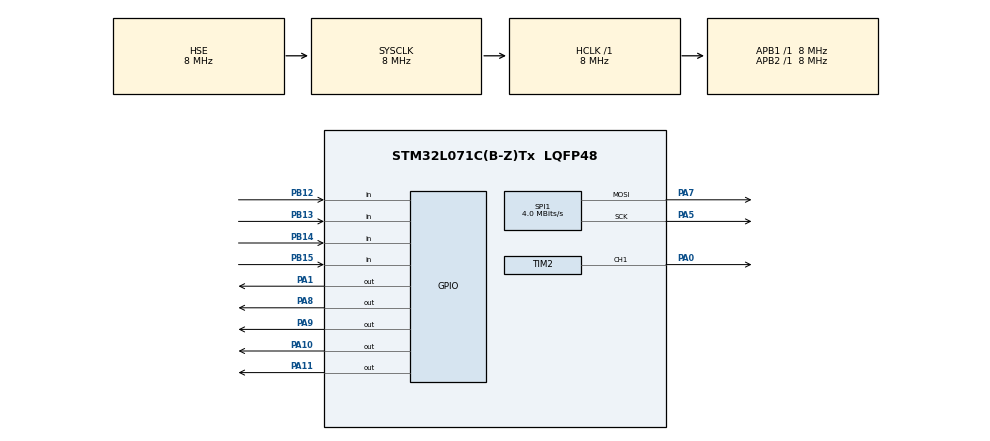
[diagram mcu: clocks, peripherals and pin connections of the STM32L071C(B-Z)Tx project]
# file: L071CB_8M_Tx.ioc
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Mcu.Family=STM32L0
Mcu.Name=STM32L071C(B-Z)Tx
Mcu.Package=LQFP48
NVIC.TIM6_IRQn=true\:0\:0\:false\:false\:true\:true\:true
PA0.Signal=S_TIM2_CH1
PA1.GPIO_Speed=GPIO_SPEED_FREQ_VERY_HIGH
PA1.PinState=GPIO_PIN_SET
PA1.Signal=GPIO_Output
PA10.GPIO_ModeDefaultOutputPP=GPIO_MODE_OUTPUT_PP
PA10.GPIO_PuPd=GPIO_PULLUP
PA10.GPIO_Speed=GPIO_SPEED_FREQ_VERY_HIGH
PA10.PinState=GPIO_PIN_SET
PA10.Signal=GPIO_Output
PA11.GPIO_ModeDefaultOutputPP=GPIO_MODE_OUTPUT_PP
PA11.GPIO_PuPd=GPIO_PULLUP
PA11.GPIO_Speed=GPIO_SPEED_FREQ_VERY_HIGH
PA11.PinState=GPIO_PIN_SET
PA11.Signal=GPIO_Output
PA13.Mode=Serial_Wire
PA13.Signal=SYS_SWDIO
PA14.Mode=Serial_Wire
PA14.Signal=SYS_SWCLK
PA5.Mode=TX_Only_Simplex_Unidirect_Master
PA5.Signal=SPI1_SCK
PA7.Mode=TX_Only_Simplex_Unidirect_Master
PA7.Signal=SPI1_MOSI
PA8.GPIO_ModeDefaultOutputPP=GPIO_MODE_OUTPUT_PP
PA8.GPIO_PuPd=GPIO_PULLUP
PA8.GPIO_Speed=GPIO_SPEED_FREQ_VERY_HIGH
PA8.PinState=GPIO_PIN_SET
PA8.Signal=GPIO_Output
PA9.GPIO_ModeDefaultOutputPP=GPIO_MODE_OUTPUT_PP
PA9.GPIO_PuPd=GPIO_PULLUP
PA9.GPIO_Speed=GPIO_SPEED_FREQ_VERY_HIGH
PA9.PinState=GPIO_PIN_SET
PA9.Signal=GPIO_Output
PB12.GPIO_Mode=GPIO_MODE_INPUT
PB12.GPIO_PuPd=GPIO_PULLDOWN
PB12.Signal=GPIO_Input
PB13.GPIO_Mode=GPIO_MODE_INPUT
PB13.GPIO_PuPd=GPIO_PULLDOWN
PB13.Signal=GPIO_Input
PB14.GPIO_Mode=GPIO_MODE_INPUT
PB14.GPIO_PuPd=GPIO_PULLDOWN
PB14.Signal=GPIO_Input
PB15.GPIO_Mode=GPIO_MODE_INPUT
PB15.GPIO_PuPd=GPIO_PULLDOWN
PB15.Signal=GPIO_Input
PC14-OSC32_IN.Mode=LSE-External-Oscillator
PC14-OSC32_IN.Signal=RCC_OSC32_IN
PC15-OSC32_OUT.Mode=LSE-External-Oscillator
PC15-OSC32_OUT.Signal=RCC_OSC32_OUT
PH0-OSC_IN.Mode=HSE-External-Oscillator
PH0-OSC_IN.Signal=RCC_OSC_IN
PH1-OSC_OUT.Mode=HSE-External-Oscillator
PH1-OSC_OUT.Signal=RCC_OSC_OUT
ProjectManager.HeapSize=0x200
ProjectManager.StackSize=0x400
ProjectManager.TargetToolchain=MDK-ARM V5.32
RCC.AHBFreq_Value=8000000
RCC.APB1Freq_Value=8000000
RCC.APB1TimFreq_Value=8000000
RCC.APB2Freq_Value=8000000
RCC.APB2TimFreq_Value=8000000
RCC.HCLKFreq_Value=8000000
RCC.HSE_VALUE=8000000
RCC.HSI16_VALUE=16000000
RCC.HSI_VALUE=16000000
RCC.MSI_VALUE=2097000
RCC.PLLMUL=RCC_PLLMUL_4
RCC.SYSCLKFreq_VALUE=8000000
RCC.SYSCLKSource=RCC_SYSCLKSOURCE_HSE
RCC.VCOOutputFreq_Value=64000000
SH.S_TIM2_CH1.0=TIM2_CH1,PWM Generation1 CH1
SPI1.CLKPolarity=SPI_POLARITY_HIGH
SPI1.CalculateBaudRate=4.0 MBits/s
SPI1.DataSize=SPI_DATASIZE_16BIT
SPI1.Direction=SPI_DIRECTION_2LINES
SPI1.Mode=SPI_MODE_MASTER
SPI1.VirtualType=VM_MASTER
TIM2.AutoReloadPreload=TIM_AUTORELOAD_PRELOAD_ENABLE
TIM2.Channel-PWM\ Generation1\ CH1=TIM_CHANNEL_1
TIM6.Period=39999
TIM6.Prescaler=3
VP_TIM6_VS_ClockSourceINT.Mode=Enable_Timer
board=custom

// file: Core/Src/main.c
/* USER CODE BEGIN Header */
/**
  ******************************************************************************
  * @file           : main.c
  * @brief          : Main program body
  ******************************************************************************
  * @attention
  *
  * <h2><center>&copy; Copyright (c) 2021 STMicroelectronics.
  * All rights reserved.</center></h2>
  *
  * This software component is licensed by ST under BSD 3-Clause license,
  * the "License"; You may not use this file except in compliance with the
  * License. You may obtain a copy of the License at:
  *                        opensource.org/licenses/BSD-3-Clause
  *
  ******************************************************************************
  */
/* USER CODE END Header */
#include "main.h"
#include "spi.h"
#include "tim.h"
#include "gpio.h"

void SystemClock_Config(void);

int main(void)
{

  /* MCU Configuration--------------------------------------------------------*/

  /* Reset of all peripherals, Initializes the Flash interface and the Systick. */
  HAL_Init();

  /* Configure the system clock */
  SystemClock_Config();

  /* Initialize all configured peripherals */
  MX_GPIO_Init();
  MX_TIM2_Init();
  MX_TIM6_Init();
  MX_SPI1_Init();
  /* USER CODE BEGIN 2 */
  Delay_Init(8);
  OLED_Init(GPIOB, 9, GPIOB, 8);
  Mod_Tx_Init(TIM2, TIM6, 695, 665);

  Mod_Tx_Start();
  /* USER CODE END 2 */

  /* Infinite loop */
  while (1)
  {

    /* USER CODE BEGIN 3 */
    Mod_Tx_Process();
    Delay_ms(100);
  }
  /* USER CODE END 3 */
}

void SystemClock_Config(void)
{
  RCC_OscInitTypeDef RCC_OscInitStruct = {0};
  RCC_ClkInitTypeDef RCC_ClkInitStruct = {0};

  /** Configure the main internal regulator output voltage
  */
  __HAL_PWR_VOLTAGESCALING_CONFIG(PWR_REGULATOR_VOLTAGE_SCALE1);
  /** Initializes the RCC Oscillators according to the specified parameters
  * in the RCC_OscInitTypeDef structure.
  */
  RCC_OscInitStruct.OscillatorType = RCC_OSCILLATORTYPE_HSE;
  RCC_OscInitStruct.HSEState = RCC_HSE_ON;
  RCC_OscInitStruct.PLL.PLLState = RCC_PLL_NONE;
  if (HAL_RCC_OscConfig(&RCC_OscInitStruct) != HAL_OK)
  {
    Error_Handler();
  }
  /** Initializes the CPU, AHB and APB buses clocks
  */
  RCC_ClkInitStruct.ClockType = RCC_CLOCKTYPE_HCLK|RCC_CLOCKTYPE_SYSCLK
                              |RCC_CLOCKTYPE_PCLK1|RCC_CLOCKTYPE_PCLK2;
  RCC_ClkInitStruct.SYSCLKSource = RCC_SYSCLKSOURCE_HSE;
  RCC_ClkInitStruct.AHBCLKDivider = RCC_SYSCLK_DIV1;
  RCC_ClkInitStruct.APB1CLKDivider = RCC_HCLK_DIV1;
  RCC_ClkInitStruct.APB2CLKDivider = RCC_HCLK_DIV1;

  if (HAL_RCC_ClockConfig(&RCC_ClkInitStruct, FLASH_LATENCY_0) != HAL_OK)
  {
    Error_Handler();
  }
}

void Error_Handler(void)
{
  __disable_irq();
  while (1)
  {
  }
}

/************************ (C) COPYRIGHT STMicroelectronics *****END OF FILE****/
